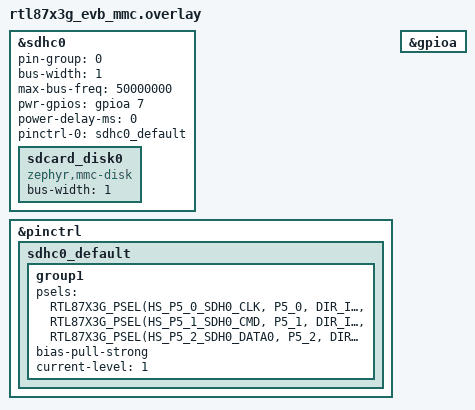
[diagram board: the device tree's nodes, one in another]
&sdhc0 {
	pin-group = <0>;
	bus-width = <1>;
	max-bus-freq = <50000000>;
	pwr-gpios = <&gpioa 7 GPIO_ACTIVE_HIGH>;
	power-delay-ms = <0>;
	pinctrl-0 = <&sdhc0_default>;
	pinctrl-names = "default";
	status = "okay";
	sdcard_disk0: sdcard_disk0 {
		bus-width = <1>;
		compatible = "zephyr,mmc-disk";
		status = "okay";
	};
};

&pinctrl {
	sdhc0_default: sdhc0_default {
			group1 {
				psels = <RTL87X3G_PSEL(HS_P5_0_SDH0_CLK, P5_0, DIR_IN, DRV_HIGH, PULL_UP)>,
					<RTL87X3G_PSEL(HS_P5_1_SDH0_CMD, P5_1, DIR_IN, DRV_HIGH, PULL_UP)>,
					<RTL87X3G_PSEL(HS_P5_2_SDH0_DATA0, P5_2, DIR_IN, DRV_HIGH, PULL_UP)>;
				bias-pull-strong;
				current-level = <1>;
			};
		};
};

&gpioa {
	status = "okay";
};
